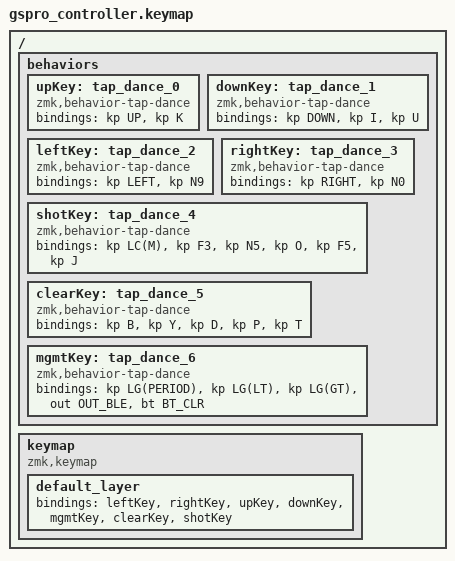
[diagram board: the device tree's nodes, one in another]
/*
 * Copyright (c) 2020 Pete Johanson, Richard Jones
 *
 * SPDX-License-Identifier: MIT
 */

#include <behaviors.dtsi>
#include <dt-bindings/zmk/keys.h>
#include <dt-bindings/zmk/bt.h>
#include <dt-bindings/zmk/outputs.h>

/ {
    behaviors {

        upKey: tap_dance_0 {
            compatible = "zmk,behavior-tap-dance";
            #binding-cells = <0>;

            // Move Up, Club Up,  
            
            bindings = <&kp UP>, <&kp K>;
        };

        downKey: tap_dance_1 {
            compatible = "zmk,behavior-tap-dance";
            #binding-cells = <0>;

            // Move Down, Club Down, Putting Mode
            
            bindings = <&kp DOWN>, <&kp I>, <&kp U>;
        };

        leftKey: tap_dance_2 {
            compatible = "zmk,behavior-tap-dance";
            #binding-cells = <0>;

            // Move Left, Prev Hole
            
            bindings = <&kp LEFT>, <&kp N9>;
        };

        rightKey: tap_dance_3 {
            compatible = "zmk,behavior-tap-dance";
            #binding-cells = <0>;

            // Move Right, Next Hole
            
            bindings = <&kp RIGHT>, <&kp N0>;
        };

        shotKey: tap_dance_4 {
            compatible = "zmk,behavior-tap-dance";
            #binding-cells = <0>;

            // Mulligan, Shot Cam, Goto Target, Goto Ball, Hole Flyover, Free Flight Cam
            
            bindings = <&kp LC(M)>, <&kp F3>, <&kp N5>, <&kp O>, <&kp F5>, <&kp J>;
        };


        clearKey: tap_dance_5 {
            compatible = "zmk,behavior-tap-dance";
            #binding-cells = <0>;

            // Clear Obstructions, Green Heatmap, Green Gridlines, Locate Pin, Scorecard
            
            bindings = <&kp B>, <&kp Y>, <&kp D>, <&kp P>, <&kp T>;
        };


        mgmtKey: tap_dance_6 {
            compatible = "zmk,behavior-tap-dance";
            #binding-cells = <0>;

             // Windows(Period)-StartSim, Windows(<)-StartSimWithSpotify, Windows(>)-Shutdown, Bluetooth output, Clear All Bluetooth
            
            bindings = <&kp LG(PERIOD)>, <&kp LG(LT)>, <&kp LG(GT)>, <&out OUT_BLE>, <&bt BT_CLR>;
        };



    };   

    keymap {
        compatible = "zmk,keymap";

        default_layer {
                // Pin0         Pin1            Pin2        Pin3        Pin4        Pin5        Pin6   
            bindings = <
 //                 &kp A &kp B &kp C &kp D &kp E &kp F &kp G 
                   &leftKey     &rightKey       &upKey      &downKey    &mgmtKey    &clearKey   &shotKey
	        >;
        };
    };
};


